# cslr_pllc2 register map
Vendor: Texas Instruments
Peripheral module from a debugger description file.
Registers are 32-bit, read-only, reset 0x0 unless marked. A register's access mark holds for its fields unless they carry their own. Offsets are as the file gives them; lines under a group give offsets from that group; [hi:lo] are bit positions; {n}, {i} and the like mark numbered series; 'fields as' and 'values as' point back to an identical list; <NAME> marks a mode.

## PLLC — This module propagates clocks to the device.
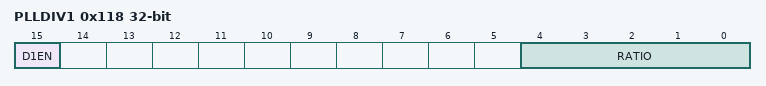
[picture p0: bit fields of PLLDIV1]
0x118 PLLDIV1 access per field — Divider 1 control--divider for SYSCLK1. Only document if this sysclk exists
  [15] D1EN rw — Divider Enable. Actual default determined by module tieoff. May lock default and make bit R only
    0=DISABLE; 1=ENABLE
  [4:0] RATIO rw — Divider ratio. Actual default determined by module tieoff. May lock default and make bit R only
    1=DIVIDE_BY_2; 4=DIVIDE_BY_5
0x138 PLLCMD access per field — Contains the command bit for the GO operation.
  [0] GOSET rw — GO operation command for SYSCLK rate change and phase alignment. Before setting this bit to 1 to initiate a GO operation, check the GOSTAT bit in the PLLSTAT register to ensure all previous GO operations have completed.
    0=CLRBIT (No effect. Write of 0 clears bit to 0.); 1=SET (Initiates GO operation. Write of 1 initiates GO operation. Once set, GOSET remains set but further writes of 1 can initiate the GO operation.)
0x13C PLLSTAT — Shows the PLL controller status.
  [0] GOSTAT — GO operation status.
    0=NONE (Go operation is not in progress. SYSCLK divide ratios are not being changed.); 1=INPROG (GO operation is in progress. SYSCLK divide ratios are being changed.)
0x140 ALNCTL reset 0x1 — Indicates if clock should be aligned during GO operation. This register should not be modified.
  [0] ALN1 — SYSCLK1 alignment. Do not change the default values of these fields.
    0=NO (Do not align SYSCLK1 to other SYSCLKs during GO operation. If SYS1 in DCHANGE is set to 1, SYSCLK1 switches to the new ratio immediately after the GOSET bit in PLLCMD is set.); 1=YES (Align SYSCLK1 when the GOSET bit in PLLCMD is set. The SYSCLK1 ratio is set to the ratio programmed in the RATIO bit in PLLDIV1.)
0x144 DCHANGE — Indicates if SYSCLK divide ratio has been modified.
  [0] SYS1 — Identifies when the SYSCLK1 divide ratio has been modified.
    0=NO (SYSCLK1 ratio has not been modified. When GOSET is set, SYSCLK1 will not be affected.); 1=YES (SYSCLK1 ratio has been modified. When GOSET is set, SYSCLK1 will change to the new ratio.)
0x150 SYSTAT reset 0x2 — Indicates SYSCLK on/off status.
  [1] SYS1ON — SYSCLK1 on status.
    0=OFF (SYSCLK1 is gated.); 1=ON (SYSCLK1 is on.)
